# SCR_TC3xx register map
Vendor: Infineon; File version: 1.0
Registers are 8-bit, read-write, reset 0x0 unless marked. A register's access mark holds for its fields unless they carry their own. Offsets are from the block's base; [hi:lo] are bit positions; {n}, {i} and the like mark numbered series.

## SCR_INT — SCR Interrupt enable and priority
Base 0x00040000
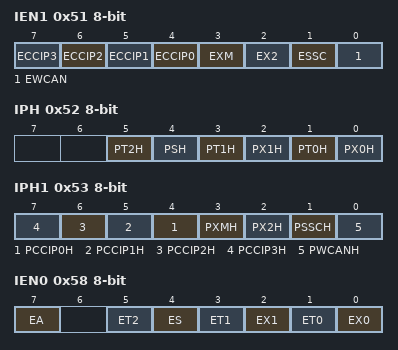
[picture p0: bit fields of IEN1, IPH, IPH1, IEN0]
0x51 IEN1 — Interrupt Enable Register 1 (SFR 0xD1)
  [n+4] ECCIP{n} (n=0..3) — Interrupt Node XINTR{n+10} Enable. [rw]
    0=XINTR{n+10}_IS_DISABLED; 1=XINTR{n+10}_IS_ENABLED
  [3] EXM — Interrupt Node XINTR9 Enable. [rw]
    0=XINTR9_IS_DISABLED; 1=XINTR9_IS_ENABLED
  [2] EX2 — Interrupt Node XINTR8 Enable. [rw]
    0=XINTR8_IS_DISABLED; 1=XINTR8_IS_ENABLED
  [1] ESSC — Interrupt Node XINTR7 Enable. [rw]
    0=XINTR7_IS_DISABLED; 1=XINTR7_IS_ENABLED
  [0] EWCAN — Interrupt Node XINTR6 Enable. [rw]
    0=XINTR6_IS_DISABLED; 1=XINTR6_IS_ENABLED
0x52 IPH — Interrupt Priority High Register (SFR 0xD2)
  [5] PT2H — Priority Level High Bit for Interrupt Node XINTR5. [rw]
  [4] PSH — Priority Level High Bit for Interrupt Node XINTR4. [rw]
  [3] PT1H — Priority Level High Bit for Interrupt Node XINTR3. [rw]
  [2] PX1H — Priority Level High Bit for Interrupt Node XINTR2. [rw]
  [1] PT0H — Priority Level High Bit for Interrupt Node XINTR1. [rw]
  [0] PX0H — Priority Level High Bit for Interrupt Node XINTR0. [rw]
0x53 IPH1 — Interrupt Priority 1 High Register (SFR 0xD3)
  [n+4] PCCIP{n}H (n=0..3) — Priority Level High Bit for Interrupt Node XINTR{n+10}. [rw]
  [3] PXMH — Priority Level High Bit for Interrupt Node XINTR9. [rw]
  [2] PX2H — Priority Level High Bit for Interrupt Node XINTR8. [rw]
  [1] PSSCH — Priority Level High Bit for Interrupt Node XINTR7. [rw]
  [0] PWCANH — Priority Level High Bit for Interrupt Node XINTR6. [rw]
0x58 IEN0 — Interrupt Enable Register 0 (SFR 0xD8)
  [7] EA — Global Interrupt Mask. [rw]
    0=ALL_PENDING_INTERRUPT_REQUESTS (All pending interrupt requests (except NMI) are blocked from the core); 1=PENDING_INTERRUPT_REQUESTS_ARE (Pending interrupt requests are not blocked from the core)
  [5] ET2 — Interrupt Node XINTR5 Enable. [rw]
    0=XINTR5_IS_DISABLED; 1=XINTR5_IS_ENABLED
  [4] ES — Interrupt Node XINTR4 Enable. [rw]
    0=XINTR4_IS_DISABLED; 1=XINTR4_IS_ENABLED
  [3] ET1 — Interrupt Node XINTR3 Enable. [rw]
    0=XINTR3_IS_DISABLED; 1=XINTR3_IS_ENABLED
  [2] EX1 — Interrupt Node XINTR2 Enable. [rw]
    0=XINTR2_IS_DISABLED; 1=XINTR2_IS_ENABLED
  [1] ET0 — Interrupt Node XINTR1 Enable. [rw]
    0=XINTR1_IS_DISABLED; 1=XINTR1_IS_ENABLED
  [0] EX0 — Interrupt Node XINTR0 Enable. [rw]
    0=XINTR0_IS_DISABLED; 1=XINTR0_IS_ENABLED
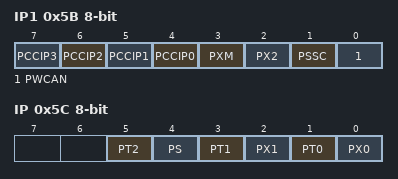
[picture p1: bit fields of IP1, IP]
0x5B IP1 — Interrupt Priority 1 Register (SFR 0xDB)
  [n+4] PCCIP{n} (n=0..3) — Priority Level Low Bit for Interrupt Node XINTR{n+10}. [rw]
  [3] PXM — Priority Level Low Bit for Interrupt Node XINTR9. [rw]
  [2] PX2 — Priority Level Low Bit for Interrupt Node XINTR8. [rw]
  [1] PSSC — Priority Level Low Bit for Interrupt Node XINTR7. [rw]
  [0] PWCAN — Priority Level Low Bit for Interrupt Node XINTR6. [rw]
0x5C IP — Interrupt Priority Register (SFR 0xDC)
  [5] PT2 — Priority Level Low Bit for Interrupt Node XINTR5. [rw]
  [4] PS — Priority Level Low Bit for Interrupt Node XINTR4. [rw]
  [3] PT1 — Priority Level Low Bit for Interrupt Node XINTR3. [rw]
  [2] PX1 — Priority Level Low Bit for Interrupt Node XINTR2. [rw]
  [1] PT0 — Priority Level Low Bit for Interrupt Node XINTR1. [rw]
  [0] PX0 — Priority Level Low Bit for Interrupt Node XINTR0. [rw]

## SCR_WDT — SCR Watchdog timer
Base 0x00040000
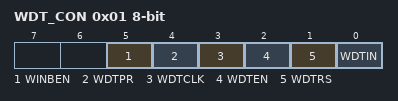
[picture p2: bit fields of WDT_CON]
0x01 WDT_CON — Watchdog Timer Control Register (SFR 0x81, RMAP 0)
  [5] WINBEN — Watchdog Window-Boundary Enable. [rw]
    0=WATCHDOG_WINDOW_BOUNDARY_FEATURE (Watchdog Window-Boundary feature is disabled (default)); 1=WATCHDOG_WINDOW_BOUNDARY_FEATURE_2 (Watchdog Window-Boundary feature is enabled)
  [4] WDTPR ro — Watchdog Prewarning Mode Flag. This bit is set to 1 when a Watchdog error is detected. The Watchdog Timer has issued an NMI trap and is in Prewarning Mode. A reset of the chip occurs after the pre-warning period has expired. [rh]
    0=NORMAL_MODE_DEFAULT_AFTER_RESET; 1=THE_WATCHDOG_IS_OPERATING_IN (The Watchdog is operating in Prewarning Mode)
  [3] WDTCLK — Watchdog Timer Clock Source Selection. [rw]
    0=V70_KHZ_CLOCK_IS_SELECTED (70 kHz clock is selected); 1=V100_MHZ_DIV_CLOCK_IS_SELECTED (100 MHz/DIV clock is selected)
  [2] WDTEN — WDT Enable. WDTEN is a protected bit. If the Protection Scheme is activated, then this bit cannot be written directly. See Section "Miscellaneous Control" for details on the protection scheme. Needs 3 wdtclk cycles to take effect. Has lower priority than WDTRS. Note:Clearing WDTEN bit to 0 during Prewarning Mode (WDTPR = 1) has no effect. [rw]
    0=WDT_IS_DISABLED; 1=WDT_IS_ENABLED
  [1] WDTRS — WDT Refresh Start. Active high. Set to start refresh operation on the watchdog timer. Cleared automatically by hardware after it is set by software. Takes 3 wdtclk cycles to take effect. Has higher priority than WDTEN. [rwh]
  [0] WDTIN — Watchdog Timer Input Frequency Selection. [rw]
    0=INPUT_FREQUENCY_IS_FWDTCLK_2; 1=INPUT_FREQUENCY_IS_FWDTCLK_128
0x02 WDT_REL — Watchdog Timer Reload Register (SFR 0x82, RMAP 0)
  [7:0] WDTREL — Watchdog Timer Reload Value. Reload value for the high byte of the WDT. After writing WDTREL, it takes 3 fWDTCLK cycles to get WDTREL active. The delay has to be regarded for WDT enable and WDT refresh operation, as otherwise the previous WDTREL value is still active. [rw]
0x03 WDT_WINB — Watchdog Window-Boundary Register (SFR 0x83, RMAP 0)
  [7:0] WDTWINB — Watchdog Window-Boundary Value. This value is programmable. Within this Window-Boundary range from 0000H to (WDTWINB|00H), the WDT cannot do a refresh, else it will cause a WDTRST to be asserted. WDTWINB is compared to WDTH. [rw]
0x04 WDT_L ro — Watchdog Timer Low Byte (SFR 0x84, RMAP 0)
  [7:0] WDT — Watchdog Timer Current Value, low byte. [rh]
0x05 WDT_H ro — Watchdog Timer High Byte (SFR 0x85, RMAP 0)
  [7:0] WDT — Watchdog Timer Current Value, high byte. [rh]
